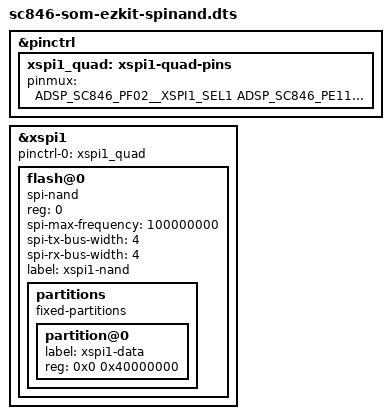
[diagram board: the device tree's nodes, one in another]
// SPDX-License-Identifier: GPL-2.0-only
/*
 * EV-SC846-SOM on the EZ-KIT carrier variant fitted with a quad SPI-NAND
 * on xSPI1 instead of the octal SPI-NOR.
 *
 * Copyright (c) 2026 Analog Devices, Inc.
 */

#include "sc846-som-ezkit.dts"

&pinctrl {
	xspi1_quad: xspi1-quad-pins {
		pinmux = <ADSP_SC846_PF02__XSPI1_SEL1
			  ADSP_SC846_PE11__XSPI1_CLK
			  ADSP_SC846_PE08__XSPI1_COTI
			  ADSP_SC846_PE07__XSPI1_CITO
			  ADSP_SC846_PE09__XSPI1_D2
			  ADSP_SC846_PE10__XSPI1_D3
			  ADSP_SC846_PE12__XSPI1_CLK>; /* PHY read loopback */
	};
};

&xspi1 {
	pinctrl-0 = <&xspi1_quad>;

	/delete-node/ flash@0;

	flash@0 {
		compatible = "spi-nand";
		reg = <0>;
		spi-max-frequency = <100000000>;
		spi-tx-bus-width = <4>;
		spi-rx-bus-width = <4>;
		label = "xspi1-nand";

		partitions {
			compatible = "fixed-partitions";
			#address-cells = <1>;
			#size-cells = <1>;

			partition@0 {
				label = "xspi1-data";
				reg = <0x0 0x40000000>;
			};
		};
	};
};
